AUTOSAR XML (schema 314)
package /ComponentType
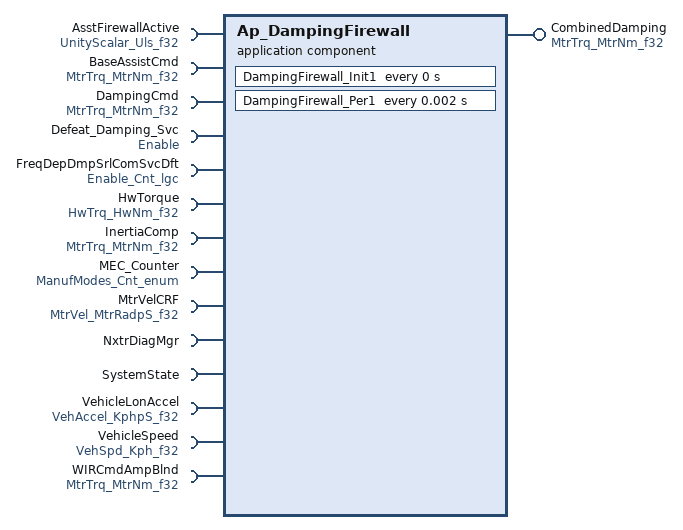
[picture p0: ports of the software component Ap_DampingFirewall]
  application software component type Ap_DampingFirewall
    provide port CombinedDamping: unqueued-sender-com-spec{data-element=MtrNm_f32, can-invalidate=false, init-value=D_ZERO_ULS_F32}, provided-interface=MtrTrq_MtrNm_f32
    14 x require port:
      AsstFirewallActive: unqueued-receiver-com-spec{data-element=Uls_f32, init-value=D_ZERO_ULS_F32}, required-interface=UnityScalar_Uls_f32
      BaseAssistCmd: unqueued-receiver-com-spec{data-element=MtrNm_f32, init-value=D_ZERO_ULS_F32}, required-interface=MtrTrq_MtrNm_f32
      DampingCmd: unqueued-receiver-com-spec{data-element=MtrNm_f32, init-value=D_ZERO_ULS_F32}, required-interface=MtrTrq_MtrNm_f32
      Defeat_Damping_Svc: unqueued-receiver-com-spec{data-element=Cnt_lgc, init-value=D_FALSE_CNT_LGC}, required-interface=Enable
      FreqDepDmpSrlComSvcDft: unqueued-receiver-com-spec{data-element=Cnt_lgc, init-value=D_FALSE_CNT_LGC}, required-interface=Enable_Cnt_lgc
      HwTorque: unqueued-receiver-com-spec{data-element=HwNm_f32, init-value=D_ZERO_ULS_F32}, required-interface=HwTrq_HwNm_f32
      InertiaComp: unqueued-receiver-com-spec{data-element=MtrNm_f32, init-value=D_ZERO_ULS_F32}, required-interface=MtrTrq_MtrNm_f32
      MEC_Counter: unqueued-receiver-com-spec{data-element=Cnt_enum, init-value=D_MANUFMODEINIT_CNT_ENUM}, required-interface=ManufModes_Cnt_enum
      MtrVelCRF: unqueued-receiver-com-spec{data-element=MtrRadpS_f32, init-value=D_ZERO_ULS_F32}, required-interface=MtrVel_MtrRadpS_f32
      NxtrDiagMgr: required-com-specs=[GetNTCActive, GetNTCFailed, GetNTCStatus, SetNTCStatus], required-interface=NxtrDiagMgr
      SystemState: required-interface=SystemState
      VehicleLonAccel: unqueued-receiver-com-spec{data-element=KphpS_f32, init-value=D_ZERO_ULS_F32}, required-interface=VehAccel_KphpS_f32
      VehicleSpeed: unqueued-receiver-com-spec{data-element=Kph_f32, init-value=D_ZERO_ULS_F32}, required-interface=VehSpd_Kph_f32
      WIRCmdAmpBlnd: unqueued-receiver-com-spec{data-element=MtrNm_f32, init-value=D_ZERO_ULS_F32}, required-interface=MtrTrq_MtrNm_f32
  internal behavior Ap_DampingFirewall_InternalBehavior: component=Ap_DampingFirewall
    timing event DampingFirewall_Init1_InitEvent: start-on-event=DampingFirewall_Init1, period=0
    timing event TMT_DampingFirewall_Per1: mode-dependency=dependent-on-mode=[SystemState.Mode.OFF, SystemState.Mode.WARMINIT], start-on-event=DampingFirewall_Per1, period=0.002
    port-api-options:
      enable-take-address=false, indirect-api=false, port=AsstFirewallActive
      enable-take-address=false, indirect-api=false, port=BaseAssistCmd
      enable-take-address=false, indirect-api=false, port=CombinedDamping
      enable-take-address=false, indirect-api=false, port=DampingCmd
      enable-take-address=false, indirect-api=false, port=Defeat_Damping_Svc
      enable-take-address=false, indirect-api=false, port=FreqDepDmpSrlComSvcDft
      enable-take-address=false, indirect-api=false, port=HwTorque
      enable-take-address=false, indirect-api=false, port=InertiaComp
      enable-take-address=false, indirect-api=false, port=MEC_Counter
      enable-take-address=false, indirect-api=false, port=MtrVelCRF
      enable-take-address=false, indirect-api=false, port=NxtrDiagMgr
      enable-take-address=false, indirect-api=false, port=SystemState
      enable-take-address=false, indirect-api=false, port=VehicleLonAccel
      enable-take-address=false, indirect-api=false, port=VehicleSpeed
      enable-take-address=false, indirect-api=false, port=WIRCmdAmpBlnd
    runnable DampingFirewall_Init1
    runnable DampingFirewall_Per1
      12 x data read access:
        READ_AsstFirewallActive_Uls_f32: data-element=AsstFirewallActive.Uls_f32
        READ_BaseAssistCmd_MtrNm_f32: data-element=BaseAssistCmd.MtrNm_f32
        READ_DampingCmd_MtrNm_f32: data-element=DampingCmd.MtrNm_f32
        READ_Defeat_Damping_Svc_Cnt_lgc: data-element=Defeat_Damping_Svc.Cnt_lgc
        READ_FreqDepDmpSrlComSvcDft_Cnt_lgc: data-element=FreqDepDmpSrlComSvcDft.Cnt_lgc
        READ_HwTorque_HwNm_f32: data-element=HwTorque.HwNm_f32
        READ_InertiaComp_MtrNm_f32: data-element=InertiaComp.MtrNm_f32
        READ_MEC_Counter_Cnt_enum: data-element=MEC_Counter.Cnt_enum
        READ_MtrVelCRF_MtrRadpS_f32: data-element=MtrVelCRF.MtrRadpS_f32
        READ_VehicleLonAccel_KphpS_f32: data-element=VehicleLonAccel.KphpS_f32
        READ_VehicleSpeed_Kph_f32: data-element=VehicleSpeed.Kph_f32
        READ_WIRCmdAmpBlnd_MtrNm_f32: data-element=WIRCmdAmpBlnd.MtrNm_f32
      data write access WRITE_CombinedDamping_MtrNm_f32: data-element=CombinedDamping.MtrNm_f32
      sync call SC_NxtrDiagMgr_SetNTCStatus: operation=NxtrDiagMgr.SetNTCStatus, timeout=0
  swc implementation Ap_DampingFirewall_Implementation: behavior=Ap_DampingFirewall_InternalBehavior
    code-descriptors:
      code Code: type=SRC
